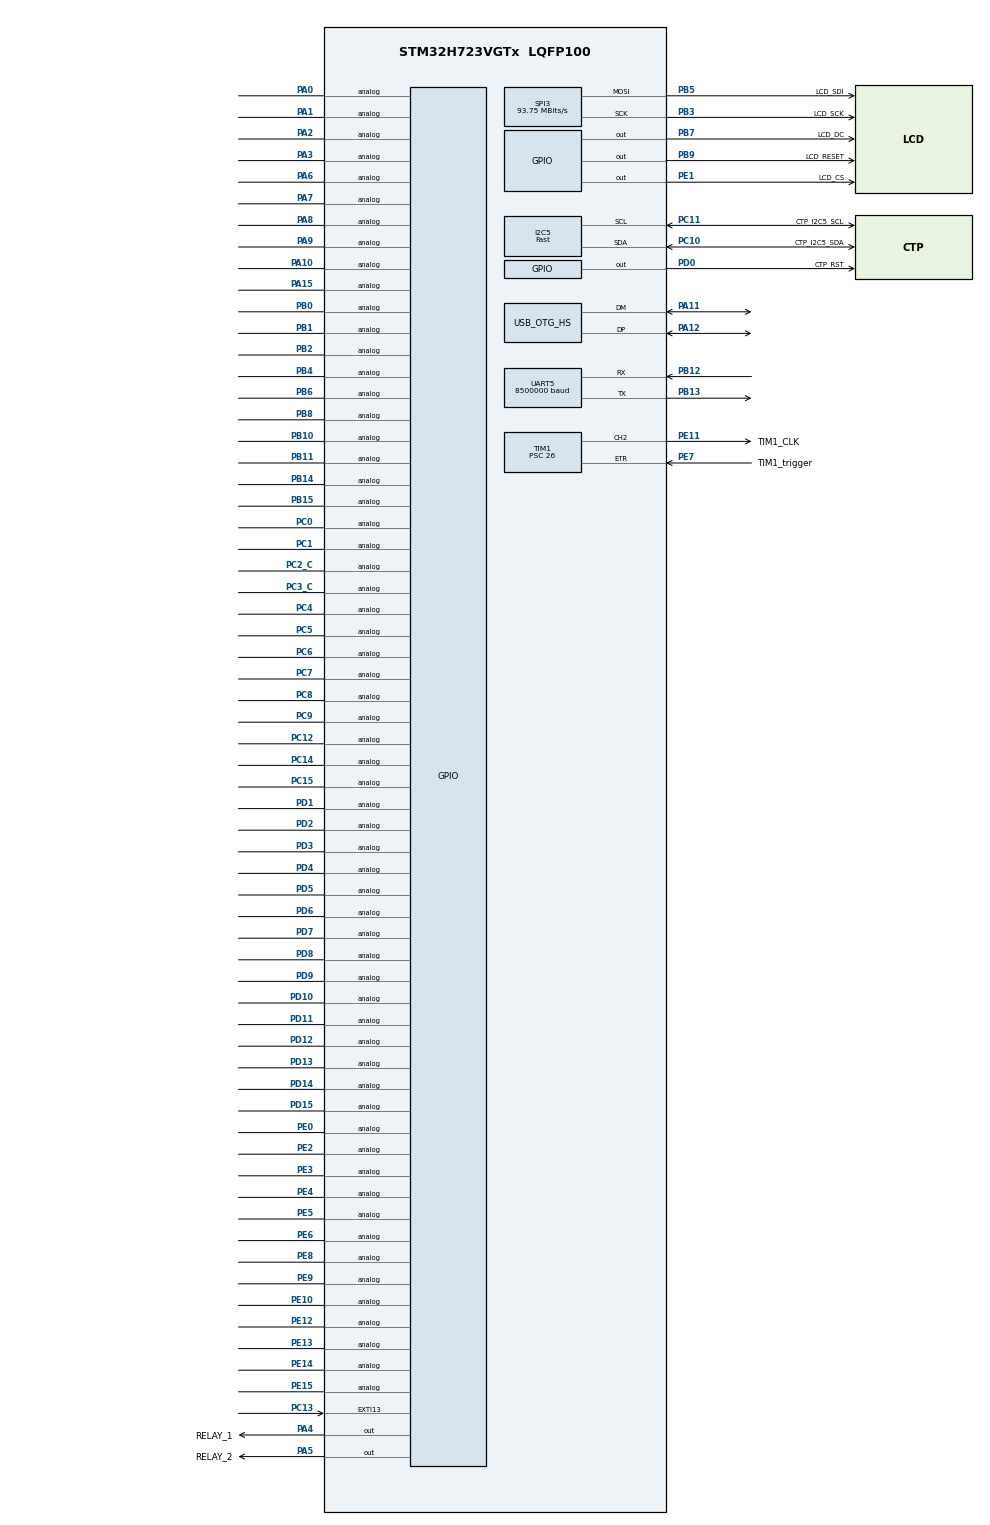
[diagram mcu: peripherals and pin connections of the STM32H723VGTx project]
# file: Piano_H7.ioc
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CORTEX_M7.AccessPermission-Cortex_Memory_Protection_Unit_Region0_Settings=MPU_REGION_PRIV_RO
CORTEX_M7.BaseAddress-Cortex_Memory_Protection_Unit_Region0_Settings=0x08000000
CORTEX_M7.CPU_DCache=Enabled
CORTEX_M7.CPU_ICache=Enabled
CORTEX_M7.Enable-Cortex_Memory_Protection_Unit_Region0_Settings=MPU_REGION_ENABLE
CORTEX_M7.IsCacheable-Cortex_Memory_Protection_Unit_Region0_Settings=MPU_ACCESS_CACHEABLE
CORTEX_M7.MPU_Control=__NULL
CORTEX_M7.Size-Cortex_Memory_Protection_Unit_Region0_Settings=MPU_REGION_SIZE_1MB
CORTEX_M7.TypeExtField-Cortex_Memory_Protection_Unit_Region0_Settings=MPU_TEX_LEVEL1
Dma.I2C5_RX.2.Direction=DMA_PERIPH_TO_MEMORY
Dma.I2C5_RX.2.EventEnable=DISABLE
Dma.I2C5_RX.2.FIFOMode=DMA_FIFOMODE_DISABLE
Dma.I2C5_RX.2.Instance=DMA2_Stream3
Dma.I2C5_RX.2.MemDataAlignment=DMA_MDATAALIGN_BYTE
Dma.I2C5_RX.2.MemInc=DMA_MINC_ENABLE
Dma.I2C5_RX.2.Mode=DMA_NORMAL
Dma.I2C5_RX.2.PeriphDataAlignment=DMA_PDATAALIGN_BYTE
Dma.I2C5_RX.2.PeriphInc=DMA_PINC_DISABLE
Dma.I2C5_RX.2.Polarity=HAL_DMAMUX_REQ_GEN_RISING
Dma.I2C5_RX.2.Priority=DMA_PRIORITY_LOW
Dma.I2C5_RX.2.RequestNumber=1
Dma.I2C5_RX.2.SignalID=NONE
Dma.I2C5_RX.2.SyncEnable=DISABLE
Dma.I2C5_RX.2.SyncPolarity=HAL_DMAMUX_SYNC_NO_EVENT
Dma.I2C5_RX.2.SyncRequestNumber=1
Dma.I2C5_RX.2.SyncSignalID=NONE
Dma.Request0=UART5_RX
Dma.Request1=SPI3_TX
Dma.Request2=I2C5_RX
Dma.SPI3_TX.1.Direction=DMA_MEMORY_TO_PERIPH
Dma.SPI3_TX.1.EventEnable=DISABLE
Dma.SPI3_TX.1.FIFOMode=DMA_FIFOMODE_DISABLE
Dma.SPI3_TX.1.Instance=DMA2_Stream1
Dma.SPI3_TX.1.MemDataAlignment=DMA_MDATAALIGN_BYTE
Dma.SPI3_TX.1.MemInc=DMA_MINC_ENABLE
Dma.SPI3_TX.1.Mode=DMA_NORMAL
Dma.SPI3_TX.1.PeriphDataAlignment=DMA_PDATAALIGN_BYTE
Dma.SPI3_TX.1.PeriphInc=DMA_PINC_DISABLE
Dma.SPI3_TX.1.Polarity=HAL_DMAMUX_REQ_GEN_RISING
Dma.SPI3_TX.1.Priority=DMA_PRIORITY_LOW
Dma.SPI3_TX.1.RequestNumber=1
Dma.SPI3_TX.1.SignalID=NONE
Dma.SPI3_TX.1.SyncEnable=DISABLE
Dma.SPI3_TX.1.SyncPolarity=HAL_DMAMUX_SYNC_NO_EVENT
Dma.SPI3_TX.1.SyncRequestNumber=1
Dma.SPI3_TX.1.SyncSignalID=NONE
Dma.UART5_RX.0.Direction=DMA_PERIPH_TO_MEMORY
Dma.UART5_RX.0.EventEnable=DISABLE
Dma.UART5_RX.0.FIFOMode=DMA_FIFOMODE_DISABLE
Dma.UART5_RX.0.Instance=DMA1_Stream2
Dma.UART5_RX.0.MemDataAlignment=DMA_MDATAALIGN_BYTE
Dma.UART5_RX.0.MemInc=DMA_MINC_ENABLE
Dma.UART5_RX.0.Mode=DMA_NORMAL
Dma.UART5_RX.0.PeriphDataAlignment=DMA_PDATAALIGN_BYTE
Dma.UART5_RX.0.PeriphInc=DMA_PINC_DISABLE
Dma.UART5_RX.0.Polarity=HAL_DMAMUX_REQ_GEN_RISING
Dma.UART5_RX.0.Priority=DMA_PRIORITY_LOW
Dma.UART5_RX.0.RequestNumber=1
Dma.UART5_RX.0.SignalID=NONE
Dma.UART5_RX.0.SyncEnable=DISABLE
Dma.UART5_RX.0.SyncPolarity=HAL_DMAMUX_SYNC_NO_EVENT
Dma.UART5_RX.0.SyncRequestNumber=1
Dma.UART5_RX.0.SyncSignalID=NONE
I2C5.CustomTiming=Disabled
I2C5.I2C_Speed_Mode=I2C_Fast
I2C5.Timing=0x00D049FB
Mcu.Family=STM32H7
Mcu.Name=STM32H723VGTx
Mcu.Package=LQFP100
NVIC.DMA1_Stream2_IRQn=true\:0\:0\:false\:false\:true\:false\:true\:true
NVIC.DMA2_Stream1_IRQn=true\:1\:0\:true\:false\:true\:false\:true\:true
NVIC.DMA2_Stream3_IRQn=true\:1\:0\:true\:false\:true\:false\:true\:true
NVIC.EXTI15_10_IRQn=true\:1\:0\:true\:false\:true\:true\:true\:true
NVIC.OTG_HS_IRQn=true\:1\:0\:false\:false\:true\:true\:true\:true
NVIC.PriorityGroup=NVIC_PRIORITYGROUP_4
NVIC.SPI3_IRQn=true\:1\:0\:true\:false\:true\:false\:true\:true
NVIC.TIM4_IRQn=true\:1\:0\:true\:false\:true\:true\:true\:true
PA0.Signal=GPIO_Analog
PA1.Signal=GPIO_Analog
PA10.Signal=GPIO_Analog
PA11.Mode=Device_Only_FS
PA11.Signal=USB_OTG_HS_DM
PA12.Mode=Device_Only_FS
PA12.Signal=USB_OTG_HS_DP
PA13(JTMS/SWDIO).Mode=Serial_Wire
PA13(JTMS/SWDIO).Signal=DEBUG_JTMS-SWDIO
PA14(JTCK/SWCLK).Mode=Serial_Wire
PA14(JTCK/SWCLK).Signal=DEBUG_JTCK-SWCLK
PA15(JTDI).Signal=GPIO_Analog
PA2.Signal=GPIO_Analog
PA3.Signal=GPIO_Analog
PA4.GPIO_Label=RELAY_1
PA4.GPIO_ModeDefaultOutputPP=GPIO_MODE_OUTPUT_PP
PA4.GPIO_PuPd=GPIO_PULLUP
PA4.Signal=GPIO_Output
PA5.GPIO_Label=RELAY_2
PA5.GPIO_ModeDefaultOutputPP=GPIO_MODE_OUTPUT_PP
PA5.GPIO_PuPd=GPIO_PULLUP
PA5.Signal=GPIO_Output
PA6.Signal=GPIO_Analog
PA7.Signal=GPIO_Analog
PA8.Signal=GPIO_Analog
PA9.Signal=GPIO_Analog
PB0.Signal=GPIO_Analog
PB1.Signal=GPIO_Analog
PB10.Signal=GPIO_Analog
PB11.Signal=GPIO_Analog
PB12.GPIO_ModeDefaultOD=GPIO_MODE_AF_PP
PB12.GPIO_PuPd=GPIO_NOPULL
PB12.GPIO_Speed=GPIO_SPEED_FREQ_MEDIUM
PB12.Mode=Multiprocessor_communication
PB12.Signal=UART5_RX
PB13.GPIO_ModeDefaultOD=GPIO_MODE_AF_PP
PB13.GPIO_PuPd=GPIO_NOPULL
PB13.GPIO_Speed=GPIO_SPEED_FREQ_MEDIUM
PB13.Mode=Multiprocessor_communication
PB13.Signal=UART5_TX
PB14.Signal=GPIO_Analog
PB15.Signal=GPIO_Analog
PB2.Signal=GPIO_Analog
PB3(JTDO/TRACESWO).GPIO_Label=LCD_SCK
PB3(JTDO/TRACESWO).GPIO_PuPd=GPIO_NOPULL
PB3(JTDO/TRACESWO).GPIO_Speed=GPIO_SPEED_FREQ_MEDIUM
PB3(JTDO/TRACESWO).Mode=TX_Only_Simplex_Unidirect_Master
PB3(JTDO/TRACESWO).Signal=SPI3_SCK
PB4(NJTRST).Signal=GPIO_Analog
PB5.GPIO_Label=LCD_SDI
PB5.GPIO_PuPd=GPIO_NOPULL
PB5.GPIO_Speed=GPIO_SPEED_FREQ_MEDIUM
PB5.Mode=TX_Only_Simplex_Unidirect_Master
PB5.Signal=SPI3_MOSI
PB6.Signal=GPIO_Analog
PB7.GPIO_Label=LCD_DC
PB7.GPIO_ModeDefaultOutputPP=GPIO_MODE_OUTPUT_PP
PB7.GPIO_PuPd=GPIO_NOPULL
PB7.GPIO_Speed=GPIO_SPEED_FREQ_LOW
PB7.PinState=GPIO_PIN_SET
PB7.Signal=GPIO_Output
PB8.Signal=GPIO_Analog
PB9.GPIO_Label=LCD_RESET
PB9.GPIO_PuPd=GPIO_NOPULL
PB9.GPIO_Speed=GPIO_SPEED_FREQ_LOW
PB9.PinState=GPIO_PIN_SET
PB9.Signal=GPIO_Output
PC0.Signal=GPIO_Analog
PC1.Signal=GPIO_Analog
PC10.GPIO_Label=CTP_I2C5_SDA
PC10.GPIO_Pu=GPIO_PULLUP
PC10.GPIO_Speed=GPIO_SPEED_FREQ_LOW
PC10.Mode=I2C
PC10.Signal=I2C5_SDA
PC11.GPIO_Label=CTP_I2C5_SCL
PC11.GPIO_Pu=GPIO_PULLUP
PC11.GPIO_Speed=GPIO_SPEED_FREQ_LOW
PC11.Mode=I2C
PC11.Signal=I2C5_SCL
PC12.Signal=GPIO_Analog
PC13.GPIO_PuPd=GPIO_PULLDOWN
PC13.Signal=GPXTI13
PC14-OSC32_IN.Signal=GPIO_Analog
PC15-OSC32_OUT.Signal=GPIO_Analog
PC2_C.Signal=GPIO_Analog
PC3_C.Signal=GPIO_Analog
PC4.Signal=GPIO_Analog
PC5.Signal=GPIO_Analog
PC6.Signal=GPIO_Analog
PC7.Signal=GPIO_Analog
PC8.Signal=GPIO_Analog
PC9.Signal=GPIO_Analog
PD0.GPIO_Label=CTP_RST
PD0.GPIO_PuPd=GPIO_NOPULL
PD0.Signal=GPIO_Output
PD1.Signal=GPIO_Analog
PD10.Signal=GPIO_Analog
PD11.Signal=GPIO_Analog
PD12.Signal=GPIO_Analog
PD13.Signal=GPIO_Analog
PD14.Signal=GPIO_Analog
PD15.Signal=GPIO_Analog
PD2.Signal=GPIO_Analog
PD3.Signal=GPIO_Analog
PD4.Signal=GPIO_Analog
PD5.Signal=GPIO_Analog
PD6.Signal=GPIO_Analog
PD7.Signal=GPIO_Analog
PD8.Signal=GPIO_Analog
PD9.Signal=GPIO_Analog
PE0.Signal=GPIO_Analog
PE1.GPIO_Label=LCD_CS
PE1.GPIO_PuPd=GPIO_NOPULL
PE1.GPIO_Speed=GPIO_SPEED_FREQ_LOW
PE1.Signal=GPIO_Output
PE10.Signal=GPIO_Analog
PE11.GPIO_Label=TIM1_CLK
PE11.GPIO_ModeDefaultPP=GPIO_MODE_AF_PP
PE11.Signal=S_TIM1_CH2
PE12.Signal=GPIO_Analog
PE13.Signal=GPIO_Analog
PE14.Signal=GPIO_Analog
PE15.Signal=GPIO_Analog
PE2.Signal=GPIO_Analog
PE3.Signal=GPIO_Analog
PE4.Signal=GPIO_Analog
PE5.Signal=GPIO_Analog
PE6.Signal=GPIO_Analog
PE7.GPIO_Label=TIM1_trigger
PE7.GPIO_PuPd=GPIO_NOPULL
PE7.Signal=S_TIM1_ETR
PE8.Signal=GPIO_Analog
PE9.Signal=GPIO_Analog
PH0-OSC_IN.Mode=HSE-External-Oscillator
PH0-OSC_IN.Signal=RCC_OSC_IN
PH1-OSC_OUT.Mode=HSE-External-Oscillator
PH1-OSC_OUT.Signal=RCC_OSC_OUT
ProjectManager.HeapSize=0x200
ProjectManager.StackSize=0x400
ProjectManager.TargetToolchain=CMake
RCC.ADCFreq_Value=272000000
RCC.APB1Freq_Value=137500000
RCC.APB2Freq_Value=137500000
RCC.APB3Freq_Value=137500000
RCC.APB4Freq_Value=137500000
RCC.CodegenConfigPeriph=true
RCC.CortexFreq_Value=550000000
RCC.D1PPRE=RCC_APB3_DIV2
RCC.D2PPRE1=RCC_APB1_DIV2
RCC.D2PPRE2=RCC_APB2_DIV2
RCC.D3PPRE=RCC_APB4_DIV2
RCC.DATA_CACHE_ENABLE=1
RCC.DIVM1=5
RCC.DIVM2=25
RCC.DIVM3=10
RCC.DIVN1=110
RCC.DIVN2=272
RCC.DIVN3=150
RCC.DIVP1=1
RCC.DIVP2=1
RCC.DIVQ3=1
RCC.DIVR1=1
RCC.EnbaleCSS=true
RCC.HCLKFreq_Value=275000000
RCC.HPRE=RCC_HCLK_DIV2
RCC.HSE_VALUE=25000000
RCC.HSIDiv=RCC_PLLSAIDIVR_4
RCC.INSTRUCTION_CACHE_ENABLE=1
RCC.LSE_Drive_CapabilityArg=+LSE_Drive_Capability
RCC.PLLSourceVirtual=RCC_PLLSOURCE_HSE
RCC.PREFETCH_ENABLE=0
RCC.RCC_MCO2Source=RCC_MCO2SOURCE_HSE
RCC.RCC_MCODiv2=RCC_MCODIV_10
RCC.SPI123CLockSelection=RCC_SPI123CLKSOURCE_PLL3
RCC.SYSCLKFreq_VALUE=550000000
RCC.SYSCLKSource=RCC_SYSCLKSOURCE_PLLCLK
RCC.USART234578CLockSelection=RCC_USART234578CLKSOURCE_PLL2
RCC.USBCLockSelection=RCC_USBCLKSOURCE_HSI48
RCC.USBFreq_Value=48000000
SH.S_TIM1_CH2.0=TIM1_CH2,PWM Generation2 CH2
SH.S_TIM1_ETR.0=TIM1_ETR,TriggerSource_ETR
SPI3.BaudRatePrescaler=SPI_BAUDRATEPRESCALER_2
SPI3.CLKPhase=SPI_PHASE_2EDGE
SPI3.CLKPolarity=SPI_POLARITY_HIGH
SPI3.CalculateBaudRate=93.75 MBits/s
SPI3.DataSize=SPI_DATASIZE_8BIT
SPI3.Direction=SPI_DIRECTION_2LINES_TXONLY
SPI3.IOSwap=SPI_IO_SWAP_ENABLE
SPI3.MasterKeepIOState=SPI_MASTER_KEEP_IO_STATE_ENABLE
SPI3.MasterReceiverAutoSusp=SPI_MASTER_RX_AUTOSUSP_DISABLE
SPI3.Mode=SPI_MODE_MASTER
SPI3.NSSPMode=SPI_NSS_PULSE_DISABLE
SPI3.NSSPolarity=SPI_NSS_POLARITY_LOW
SPI3.VirtualType=VM_MASTER
TIM1.AutoReloadPreload=TIM_AUTORELOAD_PRELOAD_ENABLE
TIM1.AutomaticOutput=TIM_AUTOMATICOUTPUT_DISABLE
TIM1.BreakPolarity=TIM_BREAKPOLARITY_LOW
TIM1.BreakState=TIM_BREAK_DISABLE
TIM1.Channel-PWM\ Generation2\ CH2=TIM_CHANNEL_2
TIM1.OC2Preload_PWM=DISABLE
TIM1.OCPolarity_2=TIM_OCPOLARITY_LOW
TIM1.Period=4
TIM1.Prescaler=26
TIM1.Pulse-PWM\ Generation2\ CH2=4
TIM1.RepetitionCounter=0
TIM1.SourceBRKDigInput=TIM_BREAKINPUTSOURCE_DISABLE
TIM1.TIM_MasterOutputTrigger=TIM_TRGO_UPDATE
TIM1.TIM_MasterSlaveMode=TIM_MASTERSLAVEMODE_DISABLE
TIM2.Prescaler=0
TIM3.Period=26
TIM3.TIM_MasterSlaveMode=TIM_MASTERSLAVEMODE_DISABLE
TIM4.Period=9
TIM4.Prescaler=27499
TIM5.AutoReloadPreload=TIM_AUTORELOAD_PRELOAD_ENABLE
TIM5.Period=4294967295
TIM5.Prescaler=274
UART5.Address=1
UART5.AddressLength=UART_ADDRESS_DETECT_7B
UART5.BaudRate=8500000
UART5.FIFOMode=UART_FIFOMODE_ENABLE
UART5.OverSampling=UART_OVERSAMPLING_8
UART5.WakeUpMethod=UART_WAKEUPMETHOD_ADDRESSMARK
UART5.WordLength=WORDLENGTH_9B
USB_OTG_HS.VirtualMode-Device_Only_FS=Device_Only_FS
VP_MEMORYMAP_VS_MEMORYMAP.Mode=CurAppReg
VP_TIM1_VS_ClockSourceINT.Mode=Internal
VP_TIM1_VS_ControllerModeGated.Mode=Gated Mode
VP_TIM2_VS_ClockSourceINT.Mode=Internal
VP_TIM3_VS_ClockSourceITR.Mode=TriggerSource_ITR0
VP_TIM3_VS_ControllerModeClock.Mode=Clock Mode
VP_TIM4_VS_ClockSourceINT.Mode=Internal
VP_TIM5_VS_ClockSourceINT.Mode=Internal
board=custom

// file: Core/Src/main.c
/* USER CODE BEGIN Header */
/**
  ******************************************************************************
  * @file           : main.c
  * @brief          : Main program body
  ******************************************************************************
  * @attention
  *
  * Copyright (c) 2025 STMicroelectronics.
  * All rights reserved.
  *
  * This software is licensed under terms that can be found in the LICENSE file
  * in the root directory of this software component.
  * If no LICENSE file comes with this software, it is provided AS-IS.
  *
  ******************************************************************************
  */
/* USER CODE END Header */
#include "main.h"
#include "dma.h"
#include "i2c.h"
#include "spi.h"
#include "tim.h"
#include "usart.h"
#include "usb_otg.h"
#include "gpio.h"

/* USER CODE BEGIN Includes */
#include "piano_h7.hpp"
/* USER CODE END Includes */

/* USER CODE BEGIN PTD */
extern void h7();
/* USER CODE END PTD */

/* USER CODE BEGIN PD */
// в слове над _bflag (флаг DFU): «после сброса уйти в выкл.»
#define POWER_OFF_FLAG 0xDEAD0FF0
/* USER CODE END PD */

/* USER CODE BEGIN PV */
// бутлоадер обнуляет только _bflag, а стеки бутлоадера и приложения начинаются ниже _bflag —
// это слово переживает сброс и прыжок из бутлоадера
extern uint32_t _bflag[]; // массив без длины: компилятор не считает доступ к слову за _bflag выходом за границы
static volatile uint32_t* const power_off_flag = &_bflag[1];
/* USER CODE END PV */

void SystemClock_Config(void);
void PeriphCommonClock_Config(void);

/* USER CODE BEGIN 0 */

// SW1 (PC13) отпущена 50 мс подряд — дребезг закончился
static void power_button_wait_release(void) {
  for (int released_ms = 0; released_ms < 50;) {
    LL_mDelay(1);
    released_ms = LL_GPIO_IsInputPinSet(GPIOC, LL_GPIO_PIN_13) ? 0 : released_ms + 1;
  }
}

// SW1 (PC13) нажата 30 мс подряд — не помеха
static int power_button_held(void) {
  for (int held_ms = 0; held_ms < 30; held_ms++) {
    if (!LL_GPIO_IsInputPinSet(GPIOC, LL_GPIO_PIN_13)) {
      return 0;
    }
    LL_mDelay(1);
  }
  return 1;
}

// «Выключено»: H7 в Stop, выводы держат заданные уровни (в Standby они ушли бы в Hi-Z).
// Выход — сбросом: по SW1 (ниже) или по NRST (TP2)
static void power_off(void) {
  // питание ядра — как в SystemClock_Config: пока ACTVOSRDY = 0, чип в ограниченном режиме Run*
  LL_PWR_ConfigSupply(LL_PWR_LDO_SUPPLY);
  while (LL_PWR_IsActiveFlag_ACTVOS() == 0) {
  }
  LL_Init1msTick(64000000); // после сброса ядро на HSI 64 МГц
  LL_AHB4_GRP1_EnableClock(LL_AHB4_GRP1_PERIPH_GPIOB | LL_AHB4_GRP1_PERIPH_GPIOC
                         | LL_AHB4_GRP1_PERIPH_GPIOD | LL_AHB4_GRP1_PERIPH_GPIOE);
  LL_APB4_GRP1_EnableClock(LL_APB4_GRP1_PERIPH_SYSCFG);

  // шина G4 в покое, как между пакетами: U_TX (PB13) = 1, TIM_CLK = 0.
  // U_RX (PB12) и TIM_TRIGG (PE7) держат R18 и R11 — там работают выходы G4, эти пины не трогать
  LL_GPIO_SetOutputPin(GPIOB, LL_GPIO_PIN_13);
  LL_GPIO_SetPinMode(GPIOB, LL_GPIO_PIN_13, LL_GPIO_MODE_OUTPUT);
  LL_GPIO_ResetOutputPin(TIM1_CLK_GPIO_Port, TIM1_CLK_Pin);
  LL_GPIO_SetPinMode(TIM1_CLK_GPIO_Port, TIM1_CLK_Pin, LL_GPIO_MODE_OUTPUT);

  // +5 В модуля дисплея не отключить: подсветку (PD6, на модуле подтянута вверх) держим в 0,
  // дисплей и тач — в сбросе
  LL_GPIO_ResetOutputPin(GPIOD, LL_GPIO_PIN_6);
  LL_GPIO_SetPinMode(GPIOD, LL_GPIO_PIN_6, LL_GPIO_MODE_OUTPUT);
  LL_GPIO_ResetOutputPin(LCD_RESET_GPIO_Port, LCD_RESET_Pin);
  LL_GPIO_SetPinMode(LCD_RESET_GPIO_Port, LCD_RESET_Pin, LL_GPIO_MODE_OUTPUT);
  LL_GPIO_ResetOutputPin(CTP_RST_GPIO_Port, CTP_RST_Pin);
  LL_GPIO_SetPinMode(CTP_RST_GPIO_Port, CTP_RST_Pin, LL_GPIO_MODE_OUTPUT);

  // SW1: R20 на плате не стоит — подтяжка вниз внутренняя. В analog EXTI фронтов не видит
  LL_GPIO_SetPinPull(GPIOC, LL_GPIO_PIN_13, LL_GPIO_PULL_DOWN);
  LL_GPIO_SetPinMode(GPIOC, LL_GPIO_PIN_13, LL_GPIO_MODE_INPUT);
  power_button_wait_release();
  // обработчик не нужен: WFI просыпается по прерыванию и при PRIMASK = 1.
  // Запрет до NVIC_EnableIRQ: иначе помеха в этом окне ушла бы в обработчик приложения — сброс
  __disable_irq();
  LL_SYSCFG_SetEXTISource(LL_SYSCFG_EXTI_PORTC, LL_SYSCFG_EXTI_LINE13);
  LL_EXTI_EnableRisingTrig_0_31(LL_EXTI_LINE_13);
  LL_EXTI_EnableIT_0_31(LL_EXTI_LINE_13);
  LL_EXTI_ClearFlag_0_31(LL_EXTI_LINE_13);
  NVIC_ClearPendingIRQ(EXTI15_10_IRQn);
  NVIC_EnableIRQ(EXTI15_10_IRQn);

  // EXTI ловит и помеху на PC13 (R20 не стоит) — включаемся, только если SW1 держат.
  // Флаги сброшены до проверки: фронт дребезга после сброса не потеряется, Stop сразу выйдет
  do {
    HAL_PWR_EnterSTOPMode(PWR_LOWPOWERREGULATOR_ON, PWR_STOPENTRY_WFI);
    LL_EXTI_ClearFlag_0_31(LL_EXTI_LINE_13);
    NVIC_ClearPendingIRQ(EXTI15_10_IRQn);
  } while (!power_button_held());

  power_button_wait_release(); // старт после отпускания — дребезг не даст лишних сбросов
  NVIC_SystemReset();
}

/* USER CODE END 0 */

int main(void)
{

  /* USER CODE BEGIN 1 */
  // H7 всегда в USB: подача питания и «off» в меню — в Stop до нажатия SW1.
  // Бутлоадер прыгает сюда, не трогая RCC, — флаги сброса доходят целыми. Они копятся до RMVF:
  // без сброса флагов любой сброс выглядел бы как подача питания
  const int power_up = LL_RCC_IsActiveFlag_PORRST() || LL_RCC_IsActiveFlag_BORRST();
  LL_RCC_ClearResetFlags();
  if (power_up || *power_off_flag == POWER_OFF_FLAG) {
    *power_off_flag = 0;
    power_off();
  }
  /* USER CODE END 1 */

  /* Enable the CPU Cache */

  /* Enable I-Cache---------------------------------------------------------*/
  SCB_EnableICache();

  /* Enable D-Cache---------------------------------------------------------*/
  SCB_EnableDCache();

  /* MCU Configuration--------------------------------------------------------*/

  /* Reset of all peripherals, Initializes the Flash interface and the Systick. */
  HAL_Init();

  /* Configure the system clock */
  SystemClock_Config();

  /* Configure the peripherals common clocks */
  PeriphCommonClock_Config();

  /* Initialize all configured peripherals */
  MX_GPIO_Init();
  MX_DMA_Init();
  MX_TIM1_Init();
  MX_TIM2_Init();
  MX_TIM3_Init();
  MX_UART5_Init();
  MX_USB_OTG_HS_PCD_Init();
  MX_I2C5_Init();
  MX_SPI3_Init();
  MX_TIM4_Init();
  MX_TIM5_Init();
  /* USER CODE BEGIN 2 */
  h7();
  /* USER CODE END 2 */

  /* Infinite loop */
  while (1) {

  }
}

void SystemClock_Config(void)
{
  LL_FLASH_SetLatency(LL_FLASH_LATENCY_3);
  while(LL_FLASH_GetLatency()!= LL_FLASH_LATENCY_3)
  {
  }
  LL_PWR_ConfigSupply(LL_PWR_LDO_SUPPLY);
  LL_PWR_SetRegulVoltageScaling(LL_PWR_REGU_VOLTAGE_SCALE0);
  while (LL_PWR_IsActiveFlag_VOS() == 0)
  {
  }
  LL_RCC_HSE_Enable();

   /* Wait till HSE is ready */
  while(LL_RCC_HSE_IsReady() != 1)
  {

  }
  LL_RCC_HSI48_Enable();

   /* Wait till HSI48 is ready */
  while(LL_RCC_HSI48_IsReady() != 1)
  {

  }
  LL_RCC_HSE_EnableCSS();
  LL_RCC_PLL_SetSource(LL_RCC_PLLSOURCE_HSE);
  LL_RCC_PLL1P_Enable();
  LL_RCC_PLL1R_Enable();
  LL_RCC_PLL1_SetVCOInputRange(LL_RCC_PLLINPUTRANGE_4_8);
  LL_RCC_PLL1_SetVCOOutputRange(LL_RCC_PLLVCORANGE_WIDE);
  LL_RCC_PLL1_SetM(5);
  LL_RCC_PLL1_SetN(110);
  LL_RCC_PLL1_SetP(1);
  LL_RCC_PLL1_SetQ(2);
  LL_RCC_PLL1_SetR(1);
  LL_RCC_PLL1_Enable();

   /* Wait till PLL is ready */
  while(LL_RCC_PLL1_IsReady() != 1)
  {
  }

   /* Intermediate AHB prescaler 2 when target frequency clock is higher than 80 MHz */
   LL_RCC_SetAHBPrescaler(LL_RCC_AHB_DIV_2);

  LL_RCC_SetSysClkSource(LL_RCC_SYS_CLKSOURCE_PLL1);

   /* Wait till System clock is ready */
  while(LL_RCC_GetSysClkSource() != LL_RCC_SYS_CLKSOURCE_STATUS_PLL1)
  {

  }
  LL_RCC_SetSysPrescaler(LL_RCC_SYSCLK_DIV_1);
  LL_RCC_SetAHBPrescaler(LL_RCC_AHB_DIV_2);
  LL_RCC_SetAPB1Prescaler(LL_RCC_APB1_DIV_2);
  LL_RCC_SetAPB2Prescaler(LL_RCC_APB2_DIV_2);
  LL_RCC_SetAPB3Prescaler(LL_RCC_APB3_DIV_2);
  LL_RCC_SetAPB4Prescaler(LL_RCC_APB4_DIV_2);
  LL_SetSystemCoreClock(550000000);

   /* Update the time base */
  if (HAL_InitTick (TICK_INT_PRIORITY) != HAL_OK)
  {
    Error_Handler();
  }
  LL_RCC_HSE_EnableCSS();
}

void PeriphCommonClock_Config(void)
{
  LL_RCC_PLL2Q_Enable();
  LL_RCC_PLL2_SetVCOInputRange(LL_RCC_PLLINPUTRANGE_1_2);
  LL_RCC_PLL2_SetVCOOutputRange(LL_RCC_PLLVCORANGE_MEDIUM);
  LL_RCC_PLL2_SetM(25);
  LL_RCC_PLL2_SetN(272);
  LL_RCC_PLL2_SetP(1);
  LL_RCC_PLL2_SetQ(2);
  LL_RCC_PLL2_SetR(2);
  LL_RCC_PLL2_Enable();

   /* Wait till PLL is ready */
  while(LL_RCC_PLL2_IsReady() != 1)
  {
  }

  LL_RCC_PLL3P_Enable();
  LL_RCC_PLL3_SetVCOInputRange(LL_RCC_PLLINPUTRANGE_2_4);
  LL_RCC_PLL3_SetVCOOutputRange(LL_RCC_PLLVCORANGE_WIDE);
  LL_RCC_PLL3_SetM(10);
  LL_RCC_PLL3_SetN(150);
  LL_RCC_PLL3_SetP(2);
  LL_RCC_PLL3_SetQ(1);
  LL_RCC_PLL3_SetR(2);
  LL_RCC_PLL3_Enable();

   /* Wait till PLL is ready */
  while(LL_RCC_PLL3_IsReady() != 1)
  {
  }

}

/* USER CODE BEGIN 4 */

// «off» в меню: выключение через сброс — из чистого состояния, тем же путём, что при подаче питания.
// Сброс сам отключает USB: у хоста устройство пропадает
void request_power_off(void) {
  *power_off_flag = POWER_OFF_FLAG;
  SCB_CleanDCache(); // иначе флаг останется в кэше и пропадёт при сбросе
  NVIC_SystemReset();
}

/* USER CODE END 4 */

void Error_Handler(void)
{
  __disable_irq();
  while (1) {
  }
}
